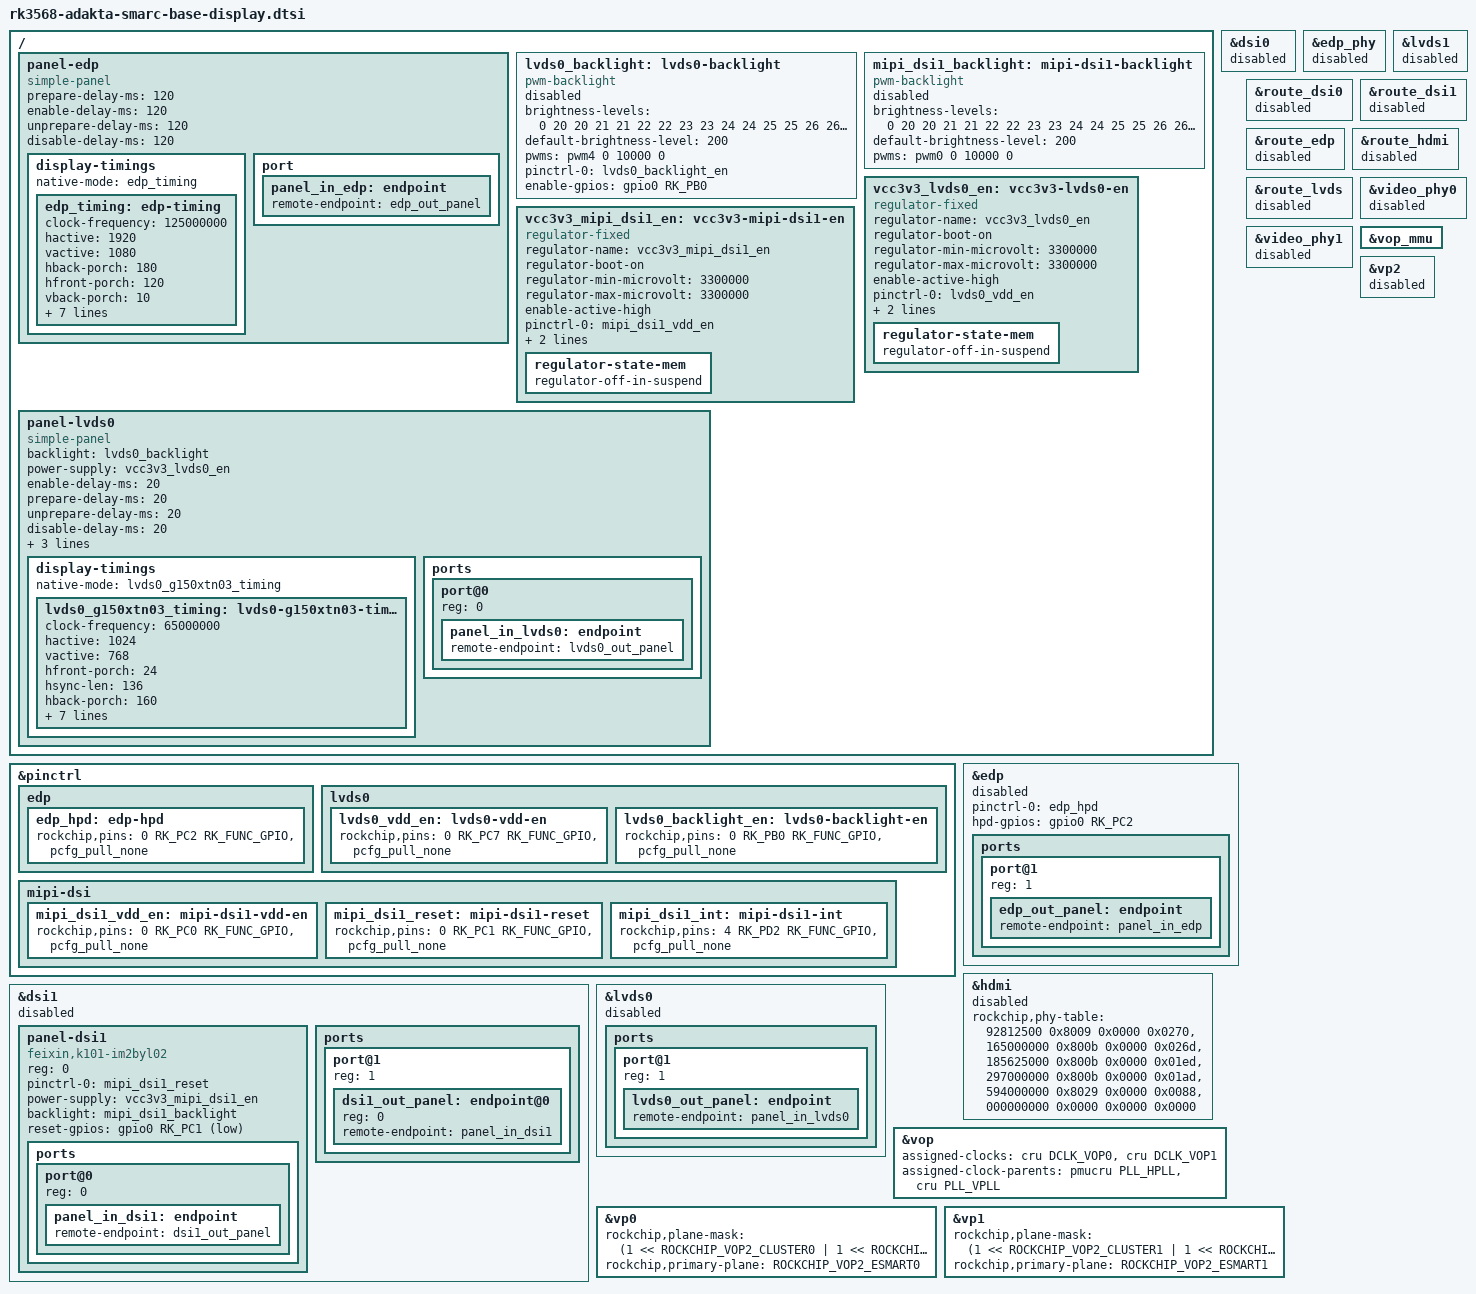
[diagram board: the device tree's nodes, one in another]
// SPDX-License-Identifier: (GPL-2.0+ OR MIT)
/*
 * Copyright (c) 2024 Adakta, Ltd.
 *
 */

#include <dt-bindings/display/drm_mipi_dsi.h>
#include <dt-bindings/display/media-bus-format.h>

/ {
	panel-edp {
		compatible = "simple-panel";
		prepare-delay-ms = <120>;
		enable-delay-ms = <120>;
		unprepare-delay-ms = <120>;
		disable-delay-ms = <120>;

		display-timings {
			native-mode = <&edp_timing>;

			edp_timing: edp-timing {
				clock-frequency = <125000000>;
				hactive = <1920>;
				vactive = <1080>;
				hback-porch = <180>;
				hfront-porch = <120>;
				vback-porch = <10>;
				vfront-porch = <10>;
				hsync-len = <20>;
				vsync-len = <10>;
				hsync-active = <0>;
				vsync-active = <0>;
				de-active = <0>;
				pixelclk-active = <0>;
			};
		};

		port {
			panel_in_edp: endpoint {
				remote-endpoint = <&edp_out_panel>;
			};
		};
	};

	lvds0_backlight: lvds0-backlight {
		compatible = "pwm-backlight";
		brightness-levels = <
			  0  20  20  21  21  22  22  23
			 23  24  24  25  25  26  26  27
			 27  28  28  29  29  30  30  31
			 31  32  32  33  33  34  34  35
			 35  36  36  37  37  38  38  39
			 40  41  42  43  44  45  46  47
			 48  49  50  51  52  53  54  55
			 56  57  58  59  60  61  62  63
			 64  65  66  67  68  69  70  71
			 72  73  74  75  76  77  78  79
			 80  81  82  83  84  85  86  87
			 88  89  90  91  92  93  94  95
			 96  97  98  99 100 101 102 103
			104 105 106 107 108 109 110 111
			112 113 114 115 116 117 118 119
			120 121 122 123 124 125 126 127
			128 129 130 131 132 133 134 135
			136 137 138 139 140 141 142 143
			144 145 146 147 148 149 150 151
			152 153 154 155 156 157 158 159
			160 161 162 163 164 165 166 167
			168 169 170 171 172 173 174 175
			176 177 178 179 180 181 182 183
			184 185 186 187 188 189 190 191
			192 193 194 195 196 197 198 199
			200 201 202 203 204 205 206 207
			208 209 210 211 212 213 214 215
			216 217 218 219 220 221 222 223
			224 225 226 227 228 229 230 231
			232 233 234 235 236 237 238 239
			240 241 242 243 244 245 246 247
			248 249 250 251 252 253 254 255
		>;
		default-brightness-level = <200>;
	};

	mipi_dsi1_backlight: mipi-dsi1-backlight {
		compatible = "pwm-backlight";
		brightness-levels = <
			  0  20  20  21  21  22  22  23
			 23  24  24  25  25  26  26  27
			 27  28  28  29  29  30  30  31
			 31  32  32  33  33  34  34  35
			 35  36  36  37  37  38  38  39
			 40  41  42  43  44  45  46  47
			 48  49  50  51  52  53  54  55
			 56  57  58  59  60  61  62  63
			 64  65  66  67  68  69  70  71
			 72  73  74  75  76  77  78  79
			 80  81  82  83  84  85  86  87
			 88  89  90  91  92  93  94  95
			 96  97  98  99 100 101 102 103
			104 105 106 107 108 109 110 111
			112 113 114 115 116 117 118 119
			120 121 122 123 124 125 126 127
			128 129 130 131 132 133 134 135
			136 137 138 139 140 141 142 143
			144 145 146 147 148 149 150 151
			152 153 154 155 156 157 158 159
			160 161 162 163 164 165 166 167
			168 169 170 171 172 173 174 175
			176 177 178 179 180 181 182 183
			184 185 186 187 188 189 190 191
			192 193 194 195 196 197 198 199
			200 201 202 203 204 205 206 207
			208 209 210 211 212 213 214 215
			216 217 218 219 220 221 222 223
			224 225 226 227 228 229 230 231
			232 233 234 235 236 237 238 239
			240 241 242 243 244 245 246 247
			248 249 250 251 252 253 254 255
		>;
		default-brightness-level = <200>;
	};

	vcc3v3_lvds0_en: vcc3v3-lvds0-en {
		compatible = "regulator-fixed";
		regulator-name = "vcc3v3_lvds0_en";
		regulator-boot-on;
		regulator-min-microvolt = <3300000>;
		regulator-max-microvolt = <3300000>;
		enable-active-high;
		pinctrl-names = "default";
		pinctrl-0 = <&lvds0_vdd_en>;
		gpio = <&gpio0 RK_PC7 GPIO_ACTIVE_HIGH>;
		vin-supply = <&vcc3v3_sys>;
		
		regulator-state-mem {
			regulator-off-in-suspend;
		};      
	};

	vcc3v3_mipi_dsi1_en: vcc3v3-mipi-dsi1-en {
		compatible = "regulator-fixed";
		regulator-name = "vcc3v3_mipi_dsi1_en";
		regulator-boot-on;
		regulator-min-microvolt = <3300000>;
		regulator-max-microvolt = <3300000>;
		enable-active-high;
		pinctrl-names = "default";
		pinctrl-0 = <&mipi_dsi1_vdd_en>;
		gpio = <&gpio0 RK_PC0 GPIO_ACTIVE_HIGH>;
		vin-supply = <&vcc3v3_sys>;
		
		regulator-state-mem {
			regulator-off-in-suspend;
		};      
	};

	panel-lvds0 {
		compatible = "simple-panel";
		backlight = <&lvds0_backlight>;
		power-supply = <&vcc3v3_lvds0_en>;
		enable-delay-ms = <20>;
		prepare-delay-ms = <20>;
		unprepare-delay-ms = <20>;
		disable-delay-ms = <20>;
		bus-format = <MEDIA_BUS_FMT_RGB888_1X7X4_SPWG>;
		width-mm = <304>;
		height-mm = <228>;

		display-timings {
			native-mode = <&lvds0_g150xtn03_timing>;

			lvds0_g150xtn03_timing: lvds0-g150xtn03-timing {
				clock-frequency = <65000000>;
				hactive = <1024>;
				vactive = <768>;
				hfront-porch = <24>;
				hsync-len = <136>;
				hback-porch = <160>;
				vfront-porch = <3>;
				vsync-len = <6>;
				vback-porch = <29>;
				hsync-active = <0>;
				vsync-active = <0>;
				de-active = <0>;
				pixelclk-active = <0>;
			};
		};

		ports {
			#address-cells = <1>;
			#size-cells = <0>;

			port@0 {
				reg = <0>;
				panel_in_lvds0: endpoint {
					remote-endpoint = <&lvds0_out_panel>;
				};
			};
		};
	};
};

&pinctrl {
	edp {
		edp_hpd: edp-hpd {
			rockchip,pins = <0 RK_PC2 RK_FUNC_GPIO &pcfg_pull_none>;
		};
	};

	lvds0 {
		lvds0_vdd_en: lvds0-vdd-en {
			rockchip,pins = <0 RK_PC7 RK_FUNC_GPIO &pcfg_pull_none>;
		};

		lvds0_backlight_en: lvds0-backlight-en {
			rockchip,pins = <0 RK_PB0 RK_FUNC_GPIO &pcfg_pull_none>;
		};
	};

	mipi-dsi {
		mipi_dsi1_vdd_en: mipi-dsi1-vdd-en {
			rockchip,pins = <0 RK_PC0 RK_FUNC_GPIO &pcfg_pull_none>;
		};

		mipi_dsi1_reset: mipi-dsi1-reset {
			rockchip,pins = <0 RK_PC1 RK_FUNC_GPIO &pcfg_pull_none>;
		};

		mipi_dsi1_int: mipi-dsi1-int {
			rockchip,pins = <4 RK_PD2 RK_FUNC_GPIO &pcfg_pull_none>;
		};
	};
};

&dsi0 {
	status = "disabled";
};

&dsi1 {
	status = "disabled";

	panel-dsi1 {
		compatible = "feixin,k101-im2byl02", "ilitek,ili9881c";
		reg = <0>;

		pinctrl-names = "default";
		pinctrl-0 = <&mipi_dsi1_reset>;

		power-supply = <&vcc3v3_mipi_dsi1_en>;
		backlight = <&mipi_dsi1_backlight>;
		reset-gpios = <&gpio0 RK_PC1 GPIO_ACTIVE_LOW>;

		ports {
			#address-cells = <1>;
			#size-cells = <0>;

			port@0 {
				reg = <0>;
				panel_in_dsi1: endpoint {
					remote-endpoint = <&dsi1_out_panel>;
				};
			};
		};
	};

	ports {
		#address-cells = <1>;
		#size-cells = <0>;

		port@1 {
			reg = <1>;
			#address-cells = <1>;
			#size-cells = <0>;

			dsi1_out_panel: endpoint@0 {
				reg = <0>;
				remote-endpoint = <&panel_in_dsi1>;
			};
		};
	};
};

&edp {
	pinctrl-names = "default";
	pinctrl-0 = <&edp_hpd>;

	hpd-gpios = <&gpio0 RK_PC2 GPIO_ACTIVE_HIGH>;
	status = "disabled";

	ports {
		port@1 {
			reg = <1>;

			edp_out_panel: endpoint {
				remote-endpoint = <&panel_in_edp>;
			};
		};
	};
};

&edp_phy {
	status = "disabled";
};

&hdmi {
	status = "disabled";
	rockchip,phy-table =
		<92812500  0x8009 0x0000 0x0270>,
		<165000000 0x800b 0x0000 0x026d>,
		<185625000 0x800b 0x0000 0x01ed>,
		<297000000 0x800b 0x0000 0x01ad>,
		<594000000 0x8029 0x0000 0x0088>,
		<000000000 0x0000 0x0000 0x0000>;
};

&lvds0 {
	status = "disabled";

	ports {
		port@1 {
			reg = <1>;

			lvds0_out_panel: endpoint {
				remote-endpoint = <&panel_in_lvds0>;
			};
		};
	};
};

&lvds0_backlight {
	pwms = <&pwm4 0 10000 0>;
	pinctrl-names = "default";
	pinctrl-0 = <&lvds0_backlight_en>;
	enable-gpios = <&gpio0 RK_PB0 GPIO_ACTIVE_HIGH>;
	status = "disabled";
};

&lvds1 {
	status = "disabled";
};

&mipi_dsi1_backlight {
	pwms = <&pwm0 0 10000 0>;
	status = "disabled";
};

&route_dsi0 {
	status = "disabled";
};

&route_dsi1 {
	status = "disabled";
};

&route_edp {
	status = "disabled";
};

&route_hdmi {
	status = "disabled";
};

&route_lvds {
	status = "disabled";
};

&video_phy0 {
	status = "disabled";
};

&video_phy1 {
	status = "disabled";
};

&vop {
	status = "okay";
	assigned-clocks = <&cru DCLK_VOP0>, <&cru DCLK_VOP1>;
	assigned-clock-parents = <&pmucru PLL_HPLL>, <&cru PLL_VPLL>;
};

&vop_mmu {
	status = "okay";
};

&vp0 {
	rockchip,plane-mask = <(1 << ROCKCHIP_VOP2_CLUSTER0 | 1 << ROCKCHIP_VOP2_ESMART0)>;
	rockchip,primary-plane = <ROCKCHIP_VOP2_ESMART0>;
};

&vp1 {
	rockchip,plane-mask = <(1 << ROCKCHIP_VOP2_CLUSTER1 | 1 << ROCKCHIP_VOP2_ESMART1)>;
	rockchip,primary-plane = <ROCKCHIP_VOP2_ESMART1>;
};

&vp2 {
	status = "disabled";
};
